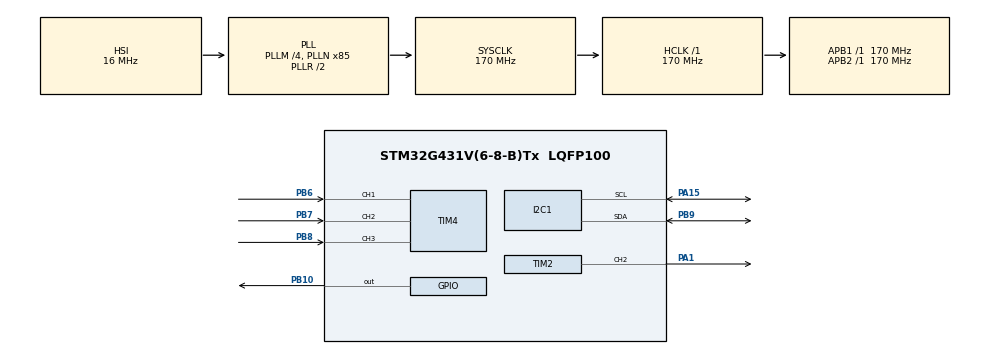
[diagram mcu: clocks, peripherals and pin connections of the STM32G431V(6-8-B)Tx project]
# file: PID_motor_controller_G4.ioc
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I2C1.OwnAddress=0x08
I2C1.Timing=0x40B285C2
Mcu.Family=STM32G4
Mcu.Name=STM32G431V(6-8-B)Tx
Mcu.Package=LQFP100
Mcu.UserConstants=TIM1_CTR_PER,7199;TIM2_PSC,99;TIM2_CTR_PER,14399;TIM4_PSC,219;TIM1_PSC,99;TIM4_CTR_PER,65535
NVIC.I2C1_ER_IRQn=true\:0\:0\:false\:false\:true\:true\:true\:true
NVIC.I2C1_EV_IRQn=true\:0\:0\:false\:false\:true\:true\:true\:true
NVIC.PriorityGroup=NVIC_PRIORITYGROUP_4
PA1.Signal=S_TIM2_CH2
PA13.Mode=Serial_Wire
PA13.Signal=SYS_JTMS-SWDIO
PA14.Mode=Serial_Wire
PA14.Signal=SYS_JTCK-SWCLK
PA15.Mode=I2C
PA15.Signal=I2C1_SCL
PB10.Signal=GPIO_Output
PB6.Signal=S_TIM4_CH1
PB7.Signal=S_TIM4_CH2
PB8-BOOT0.Signal=S_TIM4_CH3
PB9.Mode=I2C
PB9.Signal=I2C1_SDA
PF0-OSC_IN.Mode=HSE-External-Oscillator
PF0-OSC_IN.Signal=RCC_OSC_IN
PF1-OSC_OUT.Mode=HSE-External-Oscillator
PF1-OSC_OUT.Signal=RCC_OSC_OUT
ProjectManager.HeapSize=0x200
ProjectManager.StackSize=0x400
ProjectManager.TargetToolchain=STM32CubeIDE
RCC.ADC12Freq_Value=170000000
RCC.AHBFreq_Value=170000000
RCC.APB1Freq_Value=170000000
RCC.APB1TimFreq_Value=170000000
RCC.APB2Freq_Value=170000000
RCC.APB2TimFreq_Value=170000000
RCC.CortexFreq_Value=170000000
RCC.EXTERNAL_CLOCK_VALUE=12288000
RCC.HCLKFreq_Value=170000000
RCC.HSE_VALUE=24000000
RCC.HSI48_VALUE=48000000
RCC.HSI_VALUE=16000000
RCC.LSE_VALUE=32768
RCC.PLLM=RCC_PLLM_DIV4
RCC.PLLN=85
RCC.SYSCLKFreq_VALUE=170000000
RCC.SYSCLKSource=RCC_SYSCLKSOURCE_PLLCLK
RCC.USBFreq_Value=170000000
RCC.VCOOutputFreq_Value=340000000
SH.S_TIM2_CH2.0=TIM2_CH2,PWM Generation2 CH2
SH.S_TIM4_CH1.0=TIM4_CH1,Xored_Inputs_Hall_Sensor_Interface
SH.S_TIM4_CH2.0=TIM4_CH2,Xored_Inputs_Hall_Sensor_Interface
SH.S_TIM4_CH3.0=TIM4_CH3,Xored_Inputs_Hall_Sensor_Interface
TIM2.Channel-PWM\ Generation2\ CH2=TIM_CHANNEL_2
VP_SYS_VS_DBSignals.Mode=DisableDeadBatterySignals
VP_TIM1_VS_ClockSourceINT.Mode=Internal
VP_TIM2_VS_ClockSourceINT.Mode=Internal
board=custom

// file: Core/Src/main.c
/* USER CODE BEGIN Header */
/**
  ******************************************************************************
  * @file           : main.c
  * @brief          : Main program body
  ******************************************************************************
  * @attention
  *
  * Copyright (c) 2025 STMicroelectronics.
  * All rights reserved.
  *
  * This software is licensed under terms that can be found in the LICENSE file
  * in the root directory of this software component.
  * If no LICENSE file comes with this software, it is provided AS-IS.
  *
  ******************************************************************************
  */
/* USER CODE END Header */
#include "main.h"

/* USER CODE BEGIN Includes */
#include "user.h"
/* USER CODE END Includes */

TIM_HandleTypeDef htim1;
TIM_HandleTypeDef htim2;
TIM_HandleTypeDef htim4;

void SystemClock_Config(void);
static void MX_GPIO_Init(void);
static void MX_TIM4_Init(void);
static void MX_TIM1_Init(void);
static void MX_TIM2_Init(void);
static void MX_I2C1_Init(void);

int main(void)
{

  /* MCU Configuration--------------------------------------------------------*/

  /* Reset of all peripherals, Initializes the Flash interface and the Systick. */
  HAL_Init();

  /* Configure the system clock */
  SystemClock_Config();

  /* Initialize all configured peripherals */
  MX_GPIO_Init();
  MX_TIM4_Init();
  MX_TIM1_Init();
  MX_TIM2_Init();
  MX_I2C1_Init();
  /* USER CODE BEGIN 2 */
  user_init();
  /* USER CODE END 2 */

  /* Infinite loop */
  while (1)
  {

    /* USER CODE BEGIN 3 */

	  HAL_GPIO_TogglePin(GPIOB, GPIO_PIN_10);
	  HAL_Delay(500);

	/*
	 * Background tasks can be placed here.
	 * The periodic motor-control loop is called directly from the
	 * control timer callback.
	 */
  }
  /* USER CODE END 3 */
}

void SystemClock_Config(void)
{
  RCC_OscInitTypeDef RCC_OscInitStruct = {0};
  RCC_ClkInitTypeDef RCC_ClkInitStruct = {0};

  /** Configure the main internal regulator output voltage
  */
  HAL_PWREx_ControlVoltageScaling(PWR_REGULATOR_VOLTAGE_SCALE1_BOOST);

  /** Initializes the RCC Oscillators according to the specified parameters
  * in the RCC_OscInitTypeDef structure.
  */
  RCC_OscInitStruct.OscillatorType = RCC_OSCILLATORTYPE_HSI;
  RCC_OscInitStruct.HSIState = RCC_HSI_ON;
  RCC_OscInitStruct.HSICalibrationValue = RCC_HSICALIBRATION_DEFAULT;
  RCC_OscInitStruct.PLL.PLLState = RCC_PLL_ON;
  RCC_OscInitStruct.PLL.PLLSource = RCC_PLLSOURCE_HSI;
  RCC_OscInitStruct.PLL.PLLM = RCC_PLLM_DIV4;
  RCC_OscInitStruct.PLL.PLLN = 85;
  RCC_OscInitStruct.PLL.PLLP = RCC_PLLP_DIV2;
  RCC_OscInitStruct.PLL.PLLQ = RCC_PLLQ_DIV2;
  RCC_OscInitStruct.PLL.PLLR = RCC_PLLR_DIV2;
  if (HAL_RCC_OscConfig(&RCC_OscInitStruct) != HAL_OK)
  {
    Error_Handler();
  }

  /** Initializes the CPU, AHB and APB buses clocks
  */
  RCC_ClkInitStruct.ClockType = RCC_CLOCKTYPE_HCLK|RCC_CLOCKTYPE_SYSCLK
                              |RCC_CLOCKTYPE_PCLK1|RCC_CLOCKTYPE_PCLK2;
  RCC_ClkInitStruct.SYSCLKSource = RCC_SYSCLKSOURCE_PLLCLK;
  RCC_ClkInitStruct.AHBCLKDivider = RCC_SYSCLK_DIV1;
  RCC_ClkInitStruct.APB1CLKDivider = RCC_HCLK_DIV1;
  RCC_ClkInitStruct.APB2CLKDivider = RCC_HCLK_DIV1;

  if (HAL_RCC_ClockConfig(&RCC_ClkInitStruct, FLASH_LATENCY_4) != HAL_OK)
  {
    Error_Handler();
  }
}

static void MX_I2C1_Init(void)
{

  LL_I2C_InitTypeDef I2C_InitStruct = {0};

  LL_GPIO_InitTypeDef GPIO_InitStruct = {0};
  RCC_PeriphCLKInitTypeDef PeriphClkInit = {0};

  /** Initializes the peripherals clocks
  */
  PeriphClkInit.PeriphClockSelection = RCC_PERIPHCLK_I2C1;
  PeriphClkInit.I2c1ClockSelection = RCC_I2C1CLKSOURCE_PCLK1;
  if (HAL_RCCEx_PeriphCLKConfig(&PeriphClkInit) != HAL_OK)
  {
    Error_Handler();
  }

  LL_AHB2_GRP1_EnableClock(LL_AHB2_GRP1_PERIPH_GPIOA);
  LL_AHB2_GRP1_EnableClock(LL_AHB2_GRP1_PERIPH_GPIOB);
  /**I2C1 GPIO Configuration
  PA15   ------> I2C1_SCL
  PB9   ------> I2C1_SDA
  */
  GPIO_InitStruct.Pin = LL_GPIO_PIN_15;
  GPIO_InitStruct.Mode = LL_GPIO_MODE_ALTERNATE;
  GPIO_InitStruct.Speed = LL_GPIO_SPEED_FREQ_LOW;
  GPIO_InitStruct.OutputType = LL_GPIO_OUTPUT_OPENDRAIN;
  GPIO_InitStruct.Pull = LL_GPIO_PULL_NO;
  GPIO_InitStruct.Alternate = LL_GPIO_AF_4;
  LL_GPIO_Init(GPIOA, &GPIO_InitStruct);

  GPIO_InitStruct.Pin = LL_GPIO_PIN_9;
  GPIO_InitStruct.Mode = LL_GPIO_MODE_ALTERNATE;
  GPIO_InitStruct.Speed = LL_GPIO_SPEED_FREQ_LOW;
  GPIO_InitStruct.OutputType = LL_GPIO_OUTPUT_OPENDRAIN;
  GPIO_InitStruct.Pull = LL_GPIO_PULL_NO;
  GPIO_InitStruct.Alternate = LL_GPIO_AF_4;
  LL_GPIO_Init(GPIOB, &GPIO_InitStruct);

  /* Peripheral clock enable */
  LL_APB1_GRP1_EnableClock(LL_APB1_GRP1_PERIPH_I2C1);

  /* I2C1 interrupt Init */
  NVIC_SetPriority(I2C1_EV_IRQn, NVIC_EncodePriority(NVIC_GetPriorityGrouping(),0, 0));
  NVIC_EnableIRQ(I2C1_EV_IRQn);
  NVIC_SetPriority(I2C1_ER_IRQn, NVIC_EncodePriority(NVIC_GetPriorityGrouping(),0, 0));
  NVIC_EnableIRQ(I2C1_ER_IRQn);

  /** I2C Initialization
  */
  I2C_InitStruct.PeripheralMode = LL_I2C_MODE_I2C;
  I2C_InitStruct.Timing = 0x40B285C2;
  I2C_InitStruct.AnalogFilter = LL_I2C_ANALOGFILTER_ENABLE;
  I2C_InitStruct.DigitalFilter = 0;
  I2C_InitStruct.OwnAddress1 = 16;
  I2C_InitStruct.TypeAcknowledge = LL_I2C_ACK;
  I2C_InitStruct.OwnAddrSize = LL_I2C_OWNADDRESS1_7BIT;
  LL_I2C_Init(I2C1, &I2C_InitStruct);
  LL_I2C_SetOwnAddress1(I2C1, 0x08 << 1, LL_I2C_OWNADDRESS1_7BIT);
  LL_I2C_EnableOwnAddress1(I2C1);
  LL_I2C_EnableAutoEndMode(I2C1);
  LL_I2C_SetOwnAddress2(I2C1, 0, LL_I2C_OWNADDRESS2_NOMASK);
  LL_I2C_DisableOwnAddress2(I2C1);
  LL_I2C_DisableGeneralCall(I2C1);
  LL_I2C_EnableClockStretching(I2C1);

}

static void MX_TIM1_Init(void)
{

  TIM_ClockConfigTypeDef sClockSourceConfig = {0};
  TIM_MasterConfigTypeDef sMasterConfig = {0};

  htim1.Instance = TIM1;
  htim1.Init.Prescaler = 0;
  htim1.Init.CounterMode = TIM_COUNTERMODE_UP;
  htim1.Init.Period = 65535;
  htim1.Init.ClockDivision = TIM_CLOCKDIVISION_DIV1;
  htim1.Init.RepetitionCounter = 0;
  htim1.Init.AutoReloadPreload = TIM_AUTORELOAD_PRELOAD_DISABLE;
  if (HAL_TIM_Base_Init(&htim1) != HAL_OK)
  {
    Error_Handler();
  }
  sClockSourceConfig.ClockSource = TIM_CLOCKSOURCE_INTERNAL;
  if (HAL_TIM_ConfigClockSource(&htim1, &sClockSourceConfig) != HAL_OK)
  {
    Error_Handler();
  }
  sMasterConfig.MasterOutputTrigger = TIM_TRGO_RESET;
  sMasterConfig.MasterOutputTrigger2 = TIM_TRGO2_RESET;
  sMasterConfig.MasterSlaveMode = TIM_MASTERSLAVEMODE_DISABLE;
  if (HAL_TIMEx_MasterConfigSynchronization(&htim1, &sMasterConfig) != HAL_OK)
  {
    Error_Handler();
  }

}

static void MX_TIM2_Init(void)
{

  TIM_ClockConfigTypeDef sClockSourceConfig = {0};
  TIM_MasterConfigTypeDef sMasterConfig = {0};
  TIM_OC_InitTypeDef sConfigOC = {0};

  htim2.Instance = TIM2;
  htim2.Init.Prescaler = 0;
  htim2.Init.CounterMode = TIM_COUNTERMODE_UP;
  htim2.Init.Period = 4294967295;
  htim2.Init.ClockDivision = TIM_CLOCKDIVISION_DIV1;
  htim2.Init.AutoReloadPreload = TIM_AUTORELOAD_PRELOAD_DISABLE;
  if (HAL_TIM_Base_Init(&htim2) != HAL_OK)
  {
    Error_Handler();
  }
  sClockSourceConfig.ClockSource = TIM_CLOCKSOURCE_INTERNAL;
  if (HAL_TIM_ConfigClockSource(&htim2, &sClockSourceConfig) != HAL_OK)
  {
    Error_Handler();
  }
  if (HAL_TIM_PWM_Init(&htim2) != HAL_OK)
  {
    Error_Handler();
  }
  sMasterConfig.MasterOutputTrigger = TIM_TRGO_RESET;
  sMasterConfig.MasterSlaveMode = TIM_MASTERSLAVEMODE_DISABLE;
  if (HAL_TIMEx_MasterConfigSynchronization(&htim2, &sMasterConfig) != HAL_OK)
  {
    Error_Handler();
  }
  sConfigOC.OCMode = TIM_OCMODE_PWM1;
  sConfigOC.Pulse = 0;
  sConfigOC.OCPolarity = TIM_OCPOLARITY_HIGH;
  sConfigOC.OCFastMode = TIM_OCFAST_DISABLE;
  if (HAL_TIM_PWM_ConfigChannel(&htim2, &sConfigOC, TIM_CHANNEL_2) != HAL_OK)
  {
    Error_Handler();
  }
  HAL_TIM_MspPostInit(&htim2);

}

static void MX_TIM4_Init(void)
{

  TIM_HallSensor_InitTypeDef sConfig = {0};
  TIM_MasterConfigTypeDef sMasterConfig = {0};

  htim4.Instance = TIM4;
  htim4.Init.Prescaler = 0;
  htim4.Init.CounterMode = TIM_COUNTERMODE_UP;
  htim4.Init.Period = 65535;
  htim4.Init.ClockDivision = TIM_CLOCKDIVISION_DIV1;
  htim4.Init.AutoReloadPreload = TIM_AUTORELOAD_PRELOAD_DISABLE;
  sConfig.IC1Polarity = TIM_ICPOLARITY_RISING;
  sConfig.IC1Prescaler = TIM_ICPSC_DIV1;
  sConfig.IC1Filter = 0;
  sConfig.Commutation_Delay = 0;
  if (HAL_TIMEx_HallSensor_Init(&htim4, &sConfig) != HAL_OK)
  {
    Error_Handler();
  }
  sMasterConfig.MasterOutputTrigger = TIM_TRGO_OC2REF;
  sMasterConfig.MasterSlaveMode = TIM_MASTERSLAVEMODE_DISABLE;
  if (HAL_TIMEx_MasterConfigSynchronization(&htim4, &sMasterConfig) != HAL_OK)
  {
    Error_Handler();
  }

}

static void MX_GPIO_Init(void)
{
  GPIO_InitTypeDef GPIO_InitStruct = {0};

  /* GPIO Ports Clock Enable */
  __HAL_RCC_GPIOF_CLK_ENABLE();
  __HAL_RCC_GPIOA_CLK_ENABLE();
  __HAL_RCC_GPIOB_CLK_ENABLE();

  /*Configure GPIO pin Output Level */
  HAL_GPIO_WritePin(GPIOB, GPIO_PIN_10, GPIO_PIN_RESET);

  /*Configure GPIO pin : PB10 */
  GPIO_InitStruct.Pin = GPIO_PIN_10;
  GPIO_InitStruct.Mode = GPIO_MODE_OUTPUT_PP;
  GPIO_InitStruct.Pull = GPIO_NOPULL;
  GPIO_InitStruct.Speed = GPIO_SPEED_FREQ_LOW;
  HAL_GPIO_Init(GPIOB, &GPIO_InitStruct);

}

void Error_Handler(void)
{
  __disable_irq();
  while (1)
  {
  }
}
